# CIM register map
Vendor: Texas Instruments
Peripheral module from a debugger description file (folder ucd3138064A).
Registers are 32-bit, read-write, no defined reset value unless marked. A register's access mark holds for its fields unless they carry their own. Offsets are as the file gives them; lines under a group give offsets from that group; [hi:lo] are bit positions; {n}, {i} and the like mark numbered series; 'fields as' and 'values as' point back to an identical list; <NAME> marks a mode.

## CIM
0x00 IRQIVEC access not given — IRQ Index Offset Vector Register
  [7:0] IRQIVEC ro — Index vector
0x04 FIQIVEC access not given — FIQ Index Offset Vector Register
  [7:0] FIQIVEC ro — Index vector
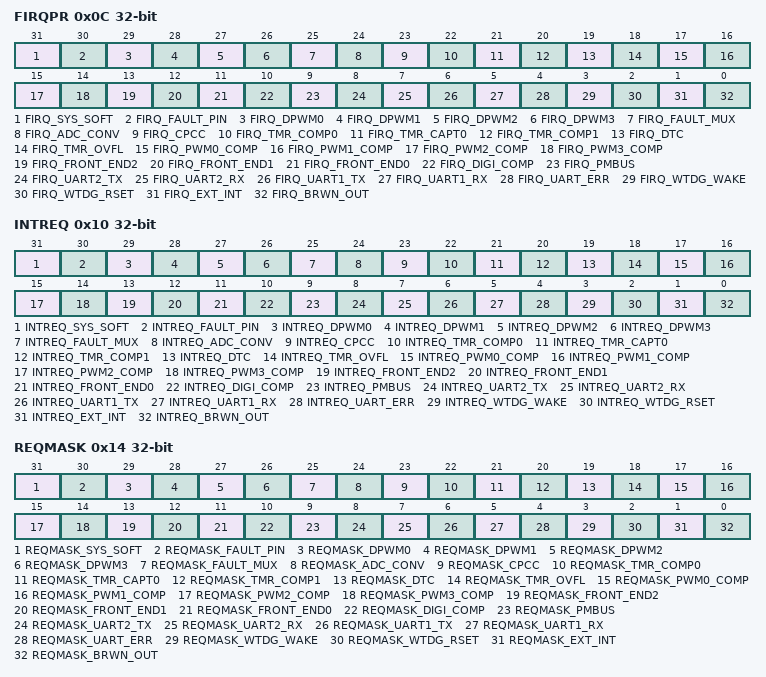
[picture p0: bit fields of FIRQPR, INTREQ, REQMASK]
0x0C FIRQPR — FIQ/IRQ Program Control Register
  [31] FIRQ_SYS_SOFT — Interrupt 31, System Software Interrupt
  [30] FIRQ_FAULT_PIN — Interrupt 30, Fault Pin Interrupt
  [29] FIRQ_DPWM0 — Interrupt 29, Every(1-16)DPWM0 switching cycles or CLF flag shutdown Interrupt
  [28] FIRQ_DPWM1 — Interrupt 28, Every(1-16)DPWM1 switching cycles or CLF flag shutdown Interrupt
  [27] FIRQ_DPWM2 — Interrupt 27, Every(1-16)DPWM2 switching cycles or CLF flag shutdown Interrupt
  [26] FIRQ_DPWM3 — Interrupt 26, Every(1-16)DPWM3 switching cycles or CLF flag shutdown Interrupt
  [25] FIRQ_FAULT_MUX — Interrupt 25, Fault Mux Interrupt
  [24] FIRQ_ADC_CONV — Interrupt 24, ADC-12 End of Conversion Interrupt
  [23] FIRQ_CPCC — Interrupt 23, CPCC Interrupt, Mode switched in CPCC module Flag needs to be read for details
  [22] FIRQ_TMR_COMP0 — Interrupt 22, 24-bit Timer Compare 0 interrupt
  [21] FIRQ_TMR_CAPT0 — Interrupt 21, 24-bit Timer Capture 0 interrupt
  [20] FIRQ_TMR_COMP1 — Interrupt 20, 24-bit Timer Compare 1 interrupt
  [19] FIRQ_DTC — Interrupt 19, 24-bit Timer Capture 1 interrupt
  [18] FIRQ_TMR_OVFL — Interrupt 18, 24-bit Timer counter overflow interrupt
  [17] FIRQ_PWM0_COMP — Interrupt 17, 16-bit Timer PWM0 counter overflow or Compare interrupt
  [16] FIRQ_PWM1_COMP — Interrupt 16, 16-bit Timer PWM1 counter overflow or Compare interrupt
  [15] FIRQ_PWM2_COMP — Interrupt 15, 16-bit Timer PWM2 counter overflow or Compare interrupt
  [14] FIRQ_PWM3_COMP — Interrupt 14, 16-bit Timer PWM3 counter overflow or Compare interrupt
  [13] FIRQ_FRONT_END2 — Interrupt 13, Front End 2 Interrupt
  [12] FIRQ_FRONT_END1 — Interrupt 12, Front End 1 Interrupt
  [11] FIRQ_FRONT_END0 — Interrupt 11, Front End 0 Interrupt
  [10] FIRQ_DIGI_COMP — Interrupt 10, Digital comparator interrupt
  [9] FIRQ_PMBUS — Interrupt 9, PMBus related interrupt
  [8] FIRQ_UART2_TX — [pin=64]Interrupt 8, UART2 TX buffer empty
  [7] FIRQ_UART2_RX — [pin=64]Interrupt 7, UART2 RX buffer has a byte
  [6] FIRQ_UART1_TX — Interrupt 6, UART1 TX buffer empty
  [5] FIRQ_UART1_RX — Interrupt 5, UART1 RX buffer has a byte
  [4] FIRQ_UART_ERR — Interrupt 4, UART or SCI error Interrupt. Frame, parity or Overrun
  [3] FIRQ_WTDG_WAKE — Interrupt 3, Wakeup interrupt when watchdog equals half of set watch time
  [2] FIRQ_WTDG_RSET — Interrupt 2, Interrupt from watchdog exceeded (reset
  [1] FIRQ_EXT_INT — [pin=64]Interrupt 1, Interrupt on one or all external input pins
  [0] FIRQ_BRWN_OUT — Interrupt 0, Brownout interrupt
0x10 INTREQ — Pending Interrupt Read Location
  [31] INTREQ_SYS_SOFT — Interrupt 31, System Software Interrupt
  [30] INTREQ_FAULT_PIN — Interrupt 30, Fault Pin Interrupt
  [29] INTREQ_DPWM0 — Interrupt 29, Every(1-16)DPWM0 switching cycles or CLF flag shutdown Interrupt
  [28] INTREQ_DPWM1 — Interrupt 28, Every(1-16)DPWM1 switching cycles or CLF flag shutdown Interrupt
  [27] INTREQ_DPWM2 — Interrupt 27, Every(1-16)DPWM2 switching cycles or CLF flag shutdown Interrupt
  [26] INTREQ_DPWM3 — Interrupt 26, Every(1-16)DPWM3 switching cycles or CLF flag shutdown Interrupt
  [25] INTREQ_FAULT_MUX — Interrupt 25, Fault Mux Interrupt
  [24] INTREQ_ADC_CONV — Interrupt 24, ADC-12 End of Conversion Interrupt
  [23] INTREQ_CPCC — Interrupt 23, CPCC Interrupt, Mode switched in CPCC module Flag needs to be read for details
  [22] INTREQ_TMR_COMP0 — Interrupt 22, 24-bit Timer Compare 0 interrupt
  [21] INTREQ_TMR_CAPT0 — Interrupt 21, 24-bit Timer Capture 0 interrupt
  [20] INTREQ_TMR_COMP1 — Interrupt 20, 24-bit Timer Compare 1 interrupt
  [19] INTREQ_DTC — Interrupt 19, 24-bit Timer Capture 1 interrupt
  [18] INTREQ_TMR_OVFL — Interrupt 18, 24-bit Timer counter overflow interrupt
  [17] INTREQ_PWM0_COMP — Interrupt 17, 16-bit Timer PWM0 counter overflow or Compare interrupt
  [16] INTREQ_PWM1_COMP — Interrupt 16, 16-bit Timer PWM1 counter overflow or Compare interrupt
  [15] INTREQ_PWM2_COMP — Interrupt 15, 16-bit Timer PWM2 counter overflow or Compare interrupt
  [14] INTREQ_PWM3_COMP — Interrupt 14, 16-bit Timer PWM3 counter overflow or Compare interrupt
  [13] INTREQ_FRONT_END2 — Interrupt 13, Front End 2 Interrupt
  [12] INTREQ_FRONT_END1 — Interrupt 12, Front End 1 Interrupt
  [11] INTREQ_FRONT_END0 — Interrupt 11, Front End 0 Interrupt
  [10] INTREQ_DIGI_COMP — Interrupt 10, Digital comparator interrupt
  [9] INTREQ_PMBUS — Interrupt 9, PMBus related interrupt
  [8] INTREQ_UART2_TX — [pin=64]Interrupt 8, UART2 TX buffer empty
  [7] INTREQ_UART2_RX — [pin=64]Interrupt 7, UART2 RX buffer has a byte
  [6] INTREQ_UART1_TX — Interrupt 6, UART1 TX buffer empty
  [5] INTREQ_UART1_RX — Interrupt 5, UART1 RX buffer has a byte
  [4] INTREQ_UART_ERR — Interrupt 4, UART or SCI error Interrupt. Frame, parity or Overrun
  [3] INTREQ_WTDG_WAKE — Interrupt 3, Wakeup interrupt when watchdog equals half of set watch time
  [2] INTREQ_WTDG_RSET — Interrupt 2, Interrupt from watchdog exceeded (reset
  [1] INTREQ_EXT_INT — [pin=64]Interrupt 1, Interrupt on one or all external input pins
  [0] INTREQ_BRWN_OUT — Interrupt 0, Brownout interrupt
0x14 REQMASK — Interrupt Mask Register
  [31] REQMASK_SYS_SOFT — Interrupt 31, System Software Interrupt
  [30] REQMASK_FAULT_PIN — Interrupt 30, Fault Pin Interrupt
  [29] REQMASK_DPWM0 — Interrupt 29, Every(1-16)DPWM0 switching cycles or CLF flag shutdown Interrupt
  [28] REQMASK_DPWM1 — Interrupt 28, Every(1-16)DPWM1 switching cycles or CLF flag shutdown Interrupt
  [27] REQMASK_DPWM2 — Interrupt 27, Every(1-16)DPWM2 switching cycles or CLF flag shutdown Interrupt
  [26] REQMASK_DPWM3 — Interrupt 26, Every(1-16)DPWM3 switching cycles or CLF flag shutdown Interrupt
  [25] REQMASK_FAULT_MUX — Interrupt 25, Fault Mux Interrupt
  [24] REQMASK_ADC_CONV — Interrupt 24, ADC-12 End of Conversion Interrupt
  [23] REQMASK_CPCC — Interrupt 23, CPCC Interrupt, Mode switched in CPCC module Flag needs to be read for details
  [22] REQMASK_TMR_COMP0 — Interrupt 22, 24-bit Timer Compare 0 interrupt
  [21] REQMASK_TMR_CAPT0 — Interrupt 21, 24-bit Timer Capture 0 interrupt
  [20] REQMASK_TMR_COMP1 — Interrupt 20, 24-bit Timer Compare 1 interrupt
  [19] REQMASK_DTC — Interrupt 19, 24-bit Timer Capture 1 interrupt
  [18] REQMASK_TMR_OVFL — Interrupt 18, 24-bit Timer counter overflow interrupt
  [17] REQMASK_PWM0_COMP — Interrupt 17, 16-bit Timer PWM0 counter overflow or Compare interrupt
  [16] REQMASK_PWM1_COMP — Interrupt 16, 16-bit Timer PWM1 counter overflow or Compare interrupt
  [15] REQMASK_PWM2_COMP — Interrupt 15, 16-bit Timer PWM2 counter overflow or Compare interrupt
  [14] REQMASK_PWM3_COMP — Interrupt 14, 16-bit Timer PWM3 counter overflow or Compare interrupt
  [13] REQMASK_FRONT_END2 — Interrupt 13, Front End 2 Interrupt
  [12] REQMASK_FRONT_END1 — Interrupt 12, Front End 1 Interrupt
  [11] REQMASK_FRONT_END0 — Interrupt 11, Front End 0 Interrupt
  [10] REQMASK_DIGI_COMP — Interrupt 10, Digital comparator interrupt
  [9] REQMASK_PMBUS — Interrupt 9, PMBus related interrupt
  [8] REQMASK_UART2_TX — [pin=64]Interrupt 8, UART2 TX buffer empty
  [7] REQMASK_UART2_RX — [pin=64]Interrupt 7, UART2 RX buffer has a byte
  [6] REQMASK_UART1_TX — Interrupt 6, UART1 TX buffer empty
  [5] REQMASK_UART1_RX — Interrupt 5, UART1 RX buffer has a byte
  [4] REQMASK_UART_ERR — Interrupt 4, UART or SCI error Interrupt. Frame, parity or Overrun
  [3] REQMASK_WTDG_WAKE — Interrupt 3, Wakeup interrupt when watchdog equals half of set watch time
  [2] REQMASK_WTDG_RSET — Interrupt 2, Interrupt from watchdog exceeded (reset
  [1] REQMASK_EXT_INT — [pin=64]Interrupt 1, Interrupt on one or all external input pins
  [0] REQMASK_BRWN_OUT — Interrupt 0, Brownout interrupt
